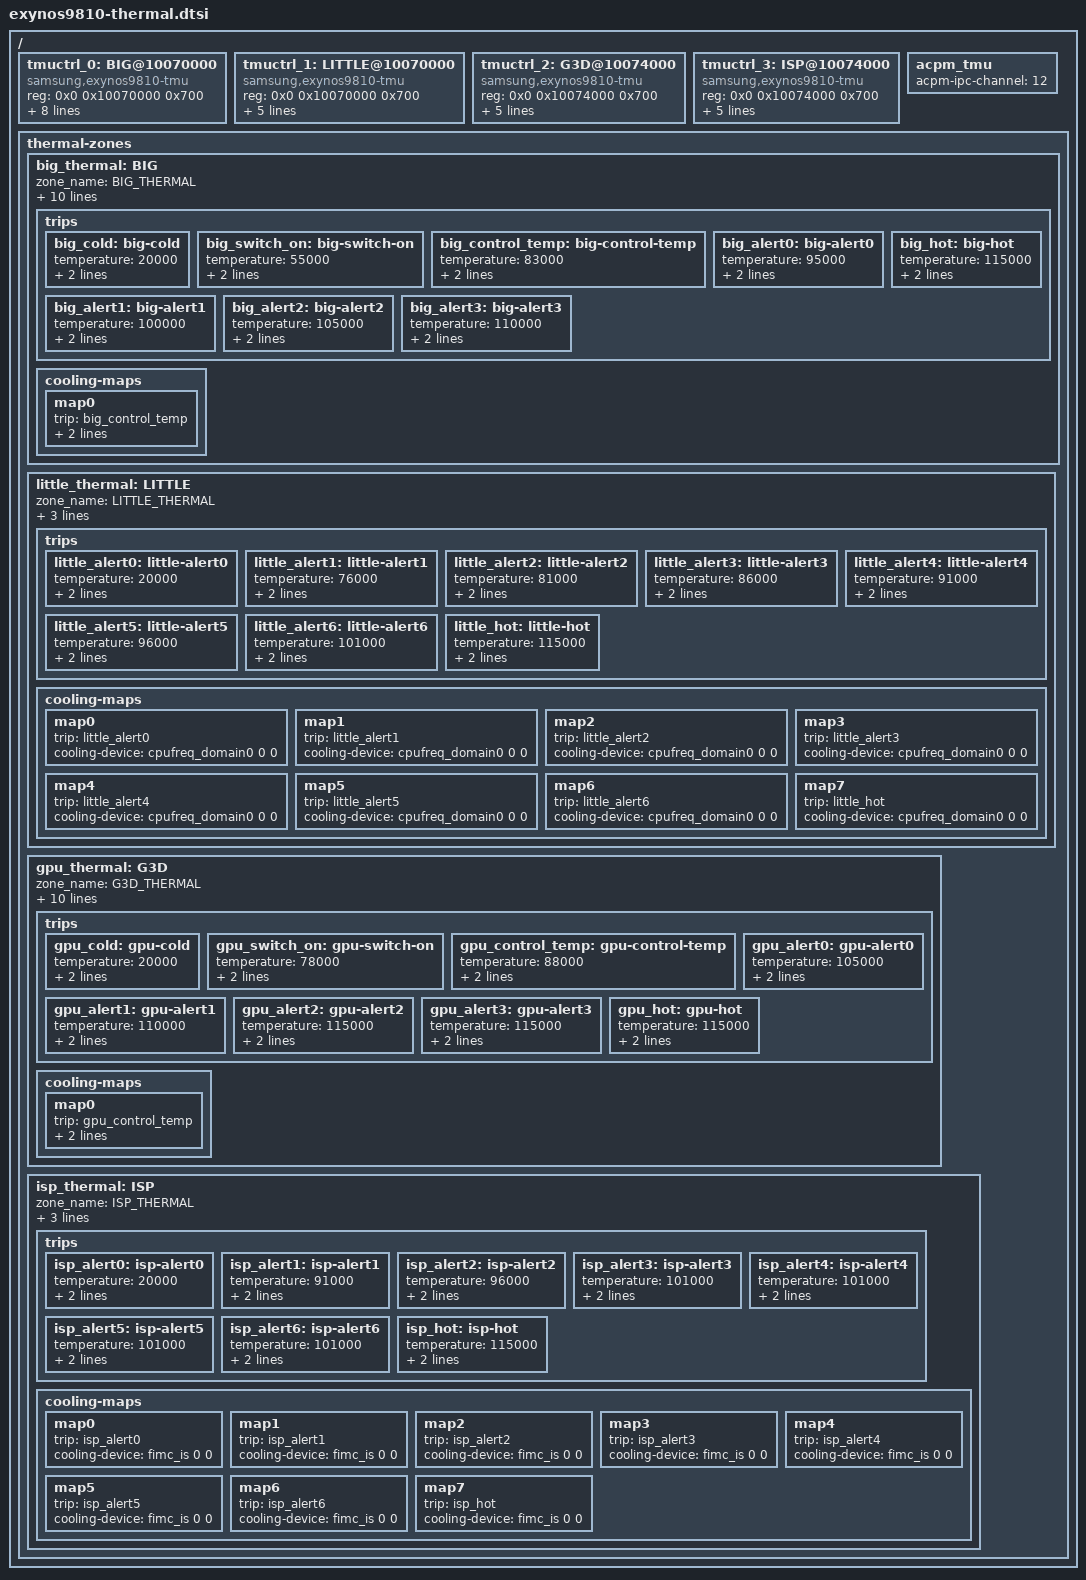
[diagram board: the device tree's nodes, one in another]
/*
 * SAMSUNG EXYNOS9810 SoC device tree source
 *
 * Copyright (c) 2017 Samsung Electronics Co., Ltd.
 *		http://www.samsung.com
 *
 * SAMSUNG EXYNOS9810 SoC device nodes are listed in this file.
 * EXYNOS9810 based board files can include this file and provide
 * values for board specfic bindings.
 *
 * This program is free software; you can redistribute it and/or modify
 * it under the terms of the GNU General Public License version 2 as
 * published by the Free Software Foundation.
 */

/ {
	tmuctrl_0: BIG@10070000 {
		compatible = "samsung,exynos9810-tmu";
		reg = <0x0 0x10070000 0x700>;
		interrupts = <0 INTREQ__TMU_TMU_TOP 0>;
		tmu_name = "BIG";
		id = <0>;
		sensors = <94>;		/* 0x5E */
		sensing_mode = "balance";
		hotplug_enable = <1>;
		hotplug_in_threshold = <91>;
		hotplug_out_threshold = <96>;
		#include "exynos9810-tmu-sensor-conf.dtsi"
	};

	tmuctrl_1: LITTLE@10070000 {
		compatible = "samsung,exynos9810-tmu";
		reg = <0x0 0x10070000 0x700>;
		interrupts = <0 INTREQ__TMU_TMU_TOP 0>;
		tmu_name = "LITTLE";
		id = <1>;
		sensors = <32>;		/* 0x20 */
		sensing_mode = "max";
		#include "exynos9810-tmu-sensor-conf.dtsi"
	};

	tmuctrl_2: G3D@10074000 {
		compatible = "samsung,exynos9810-tmu";
		reg = <0x0 0x10074000 0x700>;
		interrupts = <0 INTREQ__TMU_TMU_SUB 0>;
		tmu_name = "G3D";
		id = <2>;
		sensors = <2>;		/* 0x02 */
		sensing_mode = "max";
		#include "exynos9810-tmu-sensor-conf.dtsi"
	};

	tmuctrl_3: ISP@10074000 {
		compatible = "samsung,exynos9810-tmu";
		reg = <0x0 0x10074000 0x700>;
		interrupts = <0 INTREQ__TMU_TMU_SUB 0>;
		tmu_name = "ISP";
		id = <3>;
		sensors = <4>;		/* 0x04 */
		sensing_mode = "max";
		#include "exynos9810-tmu-sensor-conf.dtsi"
	};

	acpm_tmu {
		acpm-ipc-channel = <12>;
	};

	thermal-zones {
		big_thermal: BIG {
			zone_name  = "BIG_THERMAL";
			polling-delay-passive = <50>;
			polling-delay = <1000>;
			thermal-sensors = <&tmuctrl_0>;
			governor = "power_allocator";
			sustainable-power = <0>;
			k_po = <0>;
			k_pu = <0>;
			k_i = <0>;
			i_max = <0>;
			integral_cutoff = <0>;

			trips {
				big_cold: big-cold {
					temperature = <20000>;
					hysteresis = <5000>; /* millicelsius */
					type = "active";
				};
				big_switch_on: big-switch-on {
					temperature = <55000>; /* millicelsius */
					hysteresis = <2000>; /* millicelsius */
					type = "active";
				};
				big_control_temp: big-control-temp {
					temperature = <83000>; /* millicelsius */
					hysteresis = <5000>; /* millicelsius */
					type = "passive";
				};
				big_alert0: big-alert0 {
					temperature = <95000>; /* millicelsius */
					hysteresis = <5000>; /* millicelsius */
					type = "active";
				};
				big_alert1: big-alert1 {
					temperature = <100000>; /* millicelsius */
					hysteresis = <5000>; /* millicelsius */
					type = "active";
				};
				big_alert2: big-alert2 {
					temperature = <105000>; /* millicelsius */
					hysteresis = <5000>; /* millicelsius */
					type = "active";
				};
				big_alert3: big-alert3 {
					temperature = <110000>; /* millicelsius */
					hysteresis = <5000>; /* millicelsius */
					type = "active";
				};
				big_hot: big-hot {
					temperature = <115000>; /* millicelsius */
					hysteresis = <5000>; /* millicelsius */
					type = "hot";
				};
			};

			cooling-maps {
				map0 {
				     trip = <&big_control_temp>;
				     cooling-device = <&cpufreq_domain1 THERMAL_NO_LIMIT THERMAL_NO_LIMIT>;
			       };
			};
		};

		little_thermal: LITTLE {
			zone_name  = "LITTLE_THERMAL";
			polling-delay-passive = <0>;
			polling-delay = <0>;
			thermal-sensors = <&tmuctrl_1>;

			trips {
				little_alert0: little-alert0 {
					temperature = <20000>; /* millicelsius */
					hysteresis = <5000>; /* millicelsius */
					type = "active";
				};
				little_alert1: little-alert1 {
					temperature = <76000>; /* millicelsius */
					hysteresis = <5000>; /* millicelsius */
					type = "active";
				};
				little_alert2: little-alert2 {
					temperature = <81000>; /* millicelsius */
					hysteresis = <5000>; /* millicelsius */
					type = "active";
				};
				little_alert3: little-alert3 {
					temperature = <86000>; /* millicelsius */
					hysteresis = <5000>; /* millicelsius */
					type = "active";
				};
				little_alert4: little-alert4 {
					temperature = <91000>; /* millicelsius */
					hysteresis = <5000>; /* millicelsius */
					type = "active";
				};
				little_alert5: little-alert5 {
					temperature = <96000>; /* millicelsius */
					hysteresis = <5000>; /* millicelsius */
					type = "active";
				};
				little_alert6: little-alert6 {
					temperature = <101000>; /* millicelsius */
					hysteresis = <5000>; /* millicelsius */
					type = "active";
				};
				little_hot: little-hot {
					temperature = <115000>; /* millicelsius */
					hysteresis = <5000>; /* millicelsius */
					type = "hot";
				};
			};

			cooling-maps {
				map0 {
				     trip = <&little_alert0>;
				     /* Corresponds to 1794MHz at freq_table */
				     cooling-device = <&cpufreq_domain0 0 0>;
				};
				map1 {
				     trip = <&little_alert1>;
				     /* Corresponds to 1690MHz at freq_table */
				     cooling-device = <&cpufreq_domain0 0 0>;
			       };
				map2 {
				     trip = <&little_alert2>;
				     /* Corresponds to 1456MHz at freq_table */
				     cooling-device = <&cpufreq_domain0 0 0>;
				};
				map3 {
				     trip = <&little_alert3>;
				     /* Corresponds to 1248MHz at freq_table */
				     cooling-device = <&cpufreq_domain0 0 0>;
				};
				map4 {
				     trip = <&little_alert4>;
				     /* Corresponds to 1053MHz at freq_table */
				     cooling-device = <&cpufreq_domain0 0 0>;
				};
				map5 {
				     trip = <&little_alert5>;
				     /* Corresponds to 455MHz at freq_table */
				     cooling-device = <&cpufreq_domain0 0 0>;
			       };
				map6 {
				     trip = <&little_alert6>;
				     /* Corresponds to 455MHz at freq_table */
				     cooling-device = <&cpufreq_domain0 0 0>;
				};
				map7 {
				     trip = <&little_hot>;
				     /* Corresponds to 455MHz at freq_table */
				     cooling-device = <&cpufreq_domain0 0 0>;
				};
			};
		};

		gpu_thermal: G3D {
			zone_name  = "G3D_THERMAL";
			polling-delay-passive = <100>;
			polling-delay = <0>;
			thermal-sensors = <&tmuctrl_2>;
			governor = "power_allocator";
			sustainable-power = <0>;
			k_po = <0>;
			k_pu = <0>;
			k_i = <0>;
			i_max = <0>;
			integral_cutoff = <0>;

			trips {
				gpu_cold: gpu-cold {
					temperature = <20000>;
					hysteresis = <5000>; /* millicelsius */
					type = "active";
				};
				gpu_switch_on: gpu-switch-on {
					temperature = <78000>; /* millicelsius */
					hysteresis = <2000>; /* millicelsius */
					type = "active";
				};
				gpu_control_temp: gpu-control-temp {
					temperature = <88000>; /* millicelsius */
					hysteresis = <5000>; /* millicelsius */
					type = "passive";
				};
				gpu_alert0: gpu-alert0 {
					temperature = <105000>; /* millicelsius */
					hysteresis = <5000>; /* millicelsius */
					type = "active";
				};
				gpu_alert1: gpu-alert1 {
					temperature = <110000>; /* millicelsius */
					hysteresis = <5000>; /* millicelsius */
					type = "active";
				};
				gpu_alert2: gpu-alert2 {
					temperature = <115000>; /* millicelsius */
					hysteresis = <5000>; /* millicelsius */
					type = "active";
				};
				gpu_alert3: gpu-alert3 {
					temperature = <115000>; /* millicelsius */
					hysteresis = <5000>; /* millicelsius */
					type = "active";
				};
				gpu_hot: gpu-hot {
					temperature = <115000>; /* millicelsius */
					hysteresis = <5000>; /* millicelsius */
					type = "hot";
				};
			};

			cooling-maps {
				map0 {
				     trip = <&gpu_control_temp>;
				     cooling-device = <&mali THERMAL_NO_LIMIT THERMAL_NO_LIMIT>;
			       };
			};
		};

		isp_thermal: ISP {
			zone_name  = "ISP_THERMAL";
			polling-delay-passive = <0>;
			polling-delay = <0>;
			thermal-sensors = <&tmuctrl_3>;

			trips {
				isp_alert0: isp-alert0 {
					temperature = <20000>; /* millicelsius */
					hysteresis = <5000>; /* millicelsius */
					type = "active";
				};
				isp_alert1: isp-alert1 {
					temperature = <91000>; /* millicelsius */
					hysteresis = <5000>; /* millicelsius */
					type = "active";
				};
				isp_alert2: isp-alert2 {
					temperature = <96000>; /* millicelsius */
					hysteresis = <5000>; /* millicelsius */
					type = "active";
				};
				isp_alert3: isp-alert3 {
					temperature = <101000>; /* millicelsius */
					hysteresis = <5000>; /* millicelsius */
					type = "active";
				};
				isp_alert4: isp-alert4 {
					temperature = <101000>; /* millicelsius */
					hysteresis = <5000>; /* millicelsius */
					type = "active";
				};
				isp_alert5: isp-alert5 {
					temperature = <101000>; /* millicelsius */
					hysteresis = <5000>; /* millicelsius */
					type = "active";
				};
				isp_alert6: isp-alert6 {
					temperature = <101000>; /* millicelsius */
					hysteresis = <5000>; /* millicelsius */
					type = "active";
				};
				isp_hot: isp-hot {
					temperature = <115000>; /* millicelsius */
					hysteresis = <5000>; /* millicelsius */
					type = "hot";
				};
			};

			cooling-maps {
				map0 {
				     trip = <&isp_alert0>;
				     /* Corresponds to No limit */
				     cooling-device = <&fimc_is 0 0>;
				};
				map1 {
				     trip = <&isp_alert1>;
				     /* Corresponds to No limit */
				     cooling-device = <&fimc_is 0 0>;
			       };
				map2 {
				     trip = <&isp_alert2>;
				     /* Corresponds to 15fps at freq_table */
				     cooling-device = <&fimc_is 0 0>;
				};
				map3 {
				     trip = <&isp_alert3>;
				     /* Corresponds to 5fps at freq_table */
				     cooling-device = <&fimc_is 0 0>;
				};
				map4 {
				     trip = <&isp_alert4>;
				     /* Corresponds to 5fps at freq_table */
				     cooling-device = <&fimc_is 0 0>;
				};
				map5 {
				     trip = <&isp_alert5>;
				     /* Corresponds to 5fps at freq_table */
				     cooling-device = <&fimc_is 0 0>;
				};
				map6 {
				     trip = <&isp_alert6>;
				     /* Corresponds to 5fps at freq_table */
				     cooling-device = <&fimc_is 0 0>;
				};
				map7 {
				     trip = <&isp_hot>;
				     /* Corresponds to HW trip */
				     cooling-device = <&fimc_is 0 0>;
				};
			};
		};
	};
};
